# STM32H745xx register map
File version: 1.0
Registers are 32-bit, access not given, reset 0x0 unless marked. A register's access mark holds for its fields unless they carry their own. Offsets are from the block's base; [hi:lo] are bit positions; {n}, {i} and the like mark numbered series; 'fields as' and 'values as' point back to an identical list.

## MDMA
Base 0x52000000
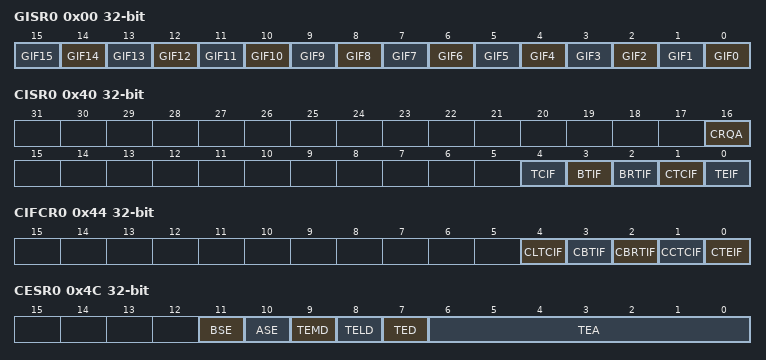
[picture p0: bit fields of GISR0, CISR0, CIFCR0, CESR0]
0x00 GISR0
  [n] GIF{n} (n=0..15)
0x40 CISR0
  [16] CRQA, [4] TCIF, [3] BTIF, [2] BRTIF, [1] CTCIF, [0] TEIF
0x44 CIFCR0
  [4] CLTCIF, [3] CBTIF, [2] CBRTIF, [1] CCTCIF, [0] CTEIF
0x4C CESR0
  [11] BSE, [10] ASE, [9] TEMD, [8] TELD, [7] TED, [6:0] TEA
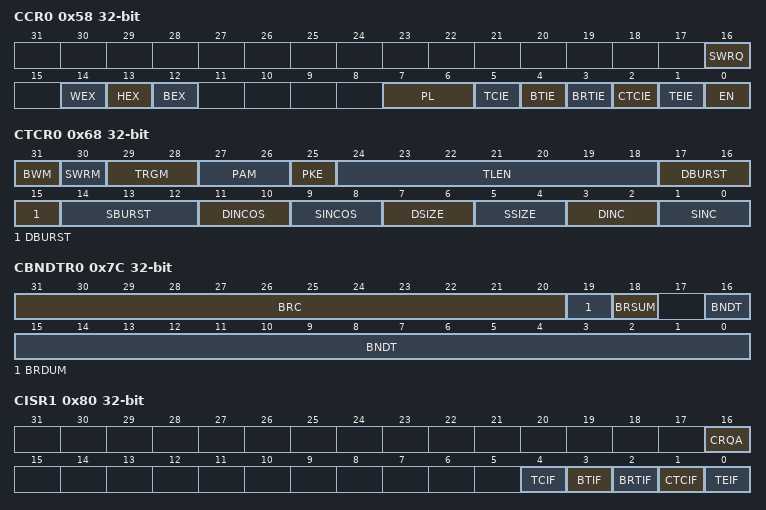
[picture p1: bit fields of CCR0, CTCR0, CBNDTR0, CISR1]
0x58 CCR0
  [16] SWRQ, [14] WEX, [13] HEX, [12] BEX, [7:6] PL, [5] TCIE, [4] BTIE, [3] BRTIE, [2] CTCIE, [1] TEIE, [0] EN
0x68 CTCR0
  [31] BWM, [30] SWRM, [29:28] TRGM, [27:26] PAM, [25] PKE, [24:18] TLEN, [17:15] DBURST, [14:12] SBURST, [11:10] DINCOS, [9:8] SINCOS, [7:6] DSIZE, [5:4] SSIZE, [3:2] DINC, [1:0] SINC
0x7C CBNDTR0
  [31:20] BRC, [19] BRDUM, [18] BRSUM, [16:0] BNDT
0x80 CISR1
  [16] CRQA, [4] TCIF, [3] BTIF, [2] BRTIF, [1] CTCIF, [0] TEIF
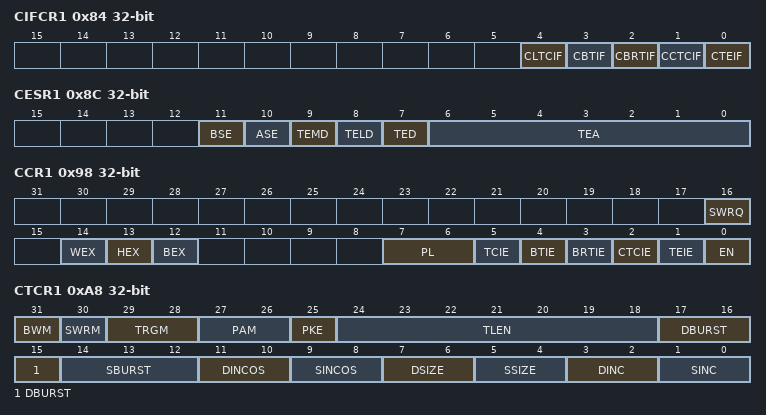
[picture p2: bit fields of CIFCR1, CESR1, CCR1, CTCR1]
0x84 CIFCR1
  [4] CLTCIF, [3] CBTIF, [2] CBRTIF, [1] CCTCIF, [0] CTEIF
0x8C CESR1
  [11] BSE, [10] ASE, [9] TEMD, [8] TELD, [7] TED, [6:0] TEA
0x94 CSAR0
  [31:0] SAR
0x98 CCR1
  fields as CCR0
0xA8 CTCR1
  fields as CTCR0
0xB0 CDAR0
  [31:0] DAR
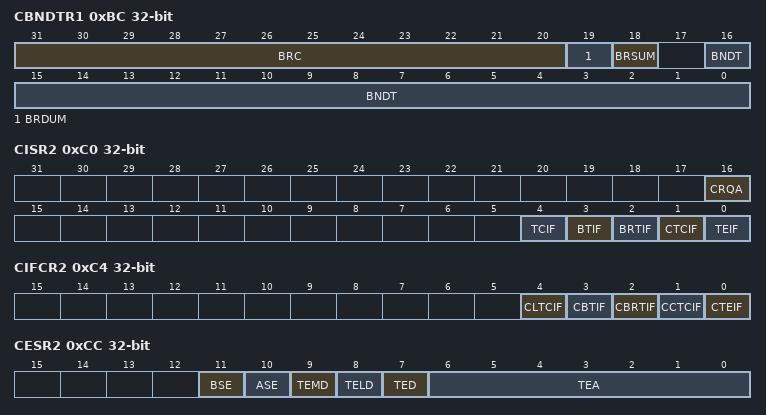
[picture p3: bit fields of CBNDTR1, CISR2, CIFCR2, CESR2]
0xBC CBNDTR1
  [31:20] BRC, [19] BRDUM, [18] BRSUM, [16:0] BNDT
0xC0 CISR2
  [16] CRQA, [4] TCIF, [3] BTIF, [2] BRTIF, [1] CTCIF, [0] TEIF
0xC4 CIFCR2
  [4] CLTCIF, [3] CBTIF, [2] CBRTIF, [1] CCTCIF, [0] CTEIF
0xCC CESR2
  [11] BSE, [10] ASE, [9] TEMD, [8] TELD, [7] TED, [6:0] TEA
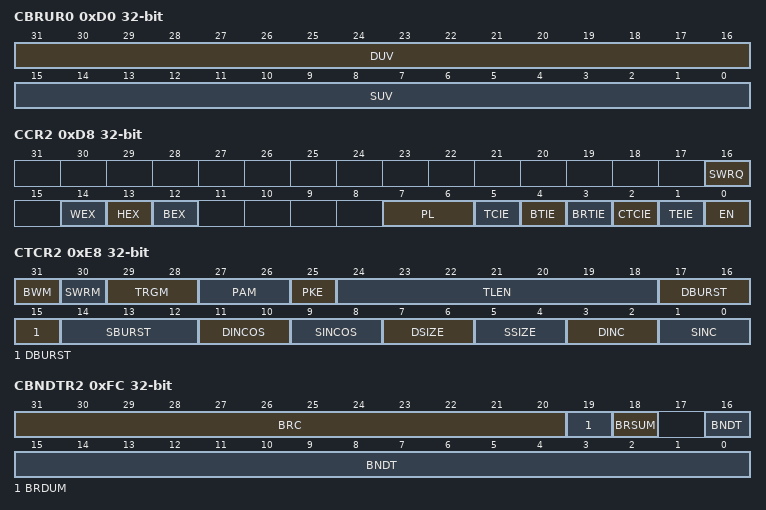
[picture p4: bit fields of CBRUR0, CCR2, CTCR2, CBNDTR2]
0xD0 CBRUR0
  [31:16] DUV, [15:0] SUV
0xD4 CSAR1
  [31:0] SAR
0xD8 CCR2
  fields as CCR0
0xE8 CTCR2
  fields as CTCR0
0xF0 CDAR1
  [31:0] DAR
0xF4 CLAR0
  [31:0] LAR
0xFC CBNDTR2
  [31:20] BRC, [19] BRDUM, [18] BRSUM, [16:0] BNDT
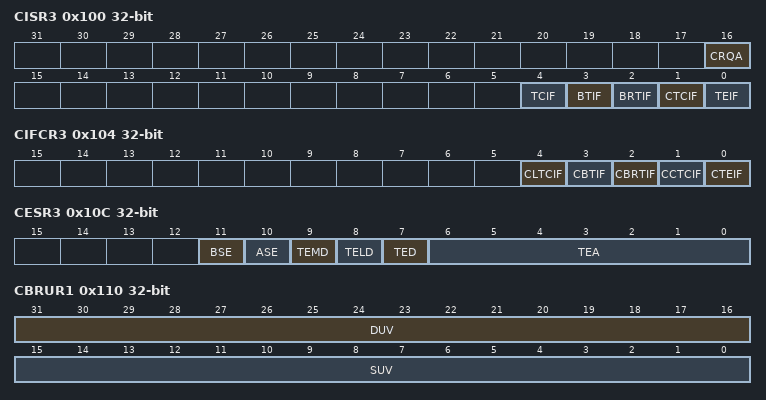
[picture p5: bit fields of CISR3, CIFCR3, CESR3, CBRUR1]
0x100 CISR3
  [16] CRQA, [4] TCIF, [3] BTIF, [2] BRTIF, [1] CTCIF, [0] TEIF
0x104 CIFCR3
  [4] CLTCIF, [3] CBTIF, [2] CBRTIF, [1] CCTCIF, [0] CTEIF
0x10C CESR3
  [11] BSE, [10] ASE, [9] TEMD, [8] TELD, [7] TED, [6:0] TEA
0x110 CBRUR1
  [31:16] DUV, [15:0] SUV
0x114 CSAR2
  [31:0] SAR
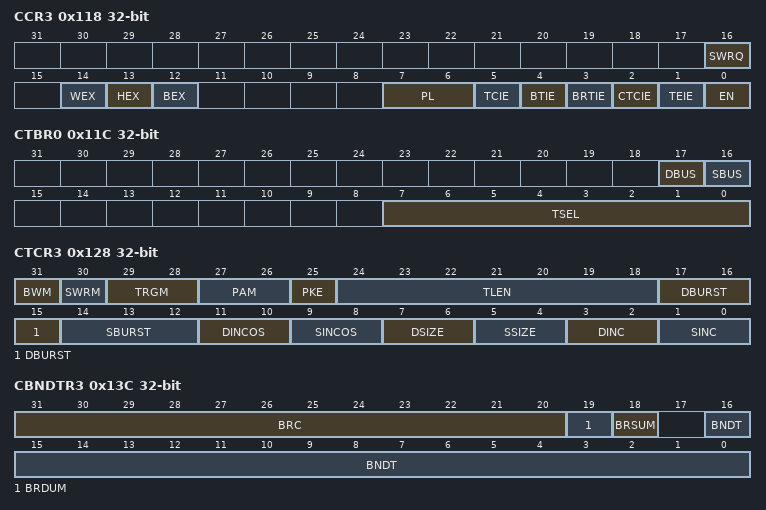
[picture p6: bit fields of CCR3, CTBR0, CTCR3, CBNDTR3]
0x118 CCR3
  fields as CCR0
0x11C CTBR0
  [17] DBUS, [16] SBUS, [7:0] TSEL
0x128 CTCR3
  fields as CTCR0
0x130 CDAR2
  [31:0] DAR
0x134 CLAR1
  [31:0] LAR
0x13C CBNDTR3
  [31:20] BRC, [19] BRDUM, [18] BRSUM, [16:0] BNDT
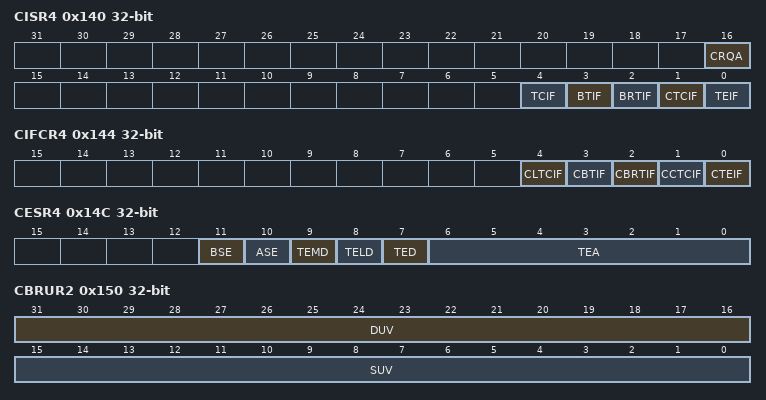
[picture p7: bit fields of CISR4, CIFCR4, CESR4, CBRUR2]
0x140 CISR4
  [16] CRQA, [4] TCIF, [3] BTIF, [2] BRTIF, [1] CTCIF, [0] TEIF
0x144 CIFCR4
  [4] CLTCIF, [3] CBTIF, [2] CBRTIF, [1] CCTCIF, [0] CTEIF
0x14C CMAR0
  [31:0] MAR
0x14C CESR4
  [11] BSE, [10] ASE, [9] TEMD, [8] TELD, [7] TED, [6:0] TEA
0x150 CBRUR2
  [31:16] DUV, [15:0] SUV
0x154 CSAR3
  [31:0] SAR
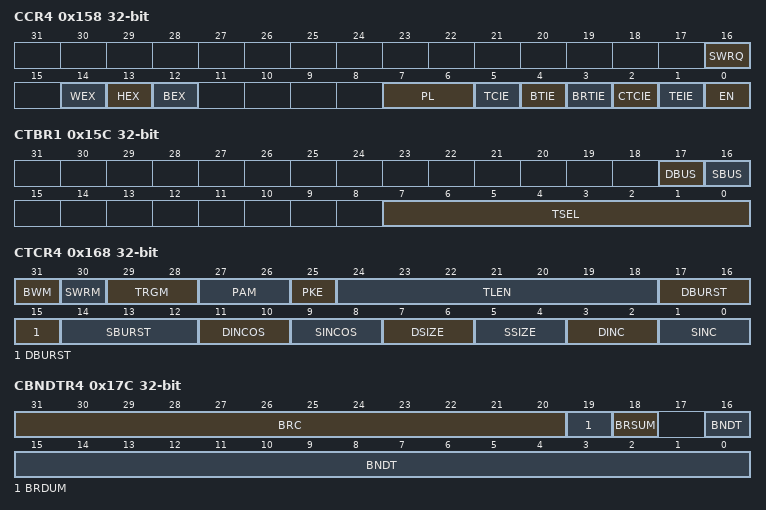
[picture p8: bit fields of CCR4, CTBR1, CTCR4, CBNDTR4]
0x158 CCR4
  fields as CCR0
0x15C CTBR1
  [17] DBUS, [16] SBUS, [7:0] TSEL
0x168 CTCR4
  fields as CTCR0
0x170 CDAR3
  [31:0] DAR
0x174 CLAR2
  [31:0] LAR
0x17C CBNDTR4
  [31:20] BRC, [19] BRDUM, [18] BRSUM, [16:0] BNDT
0x180 CMDR0
  [31:0] MDR
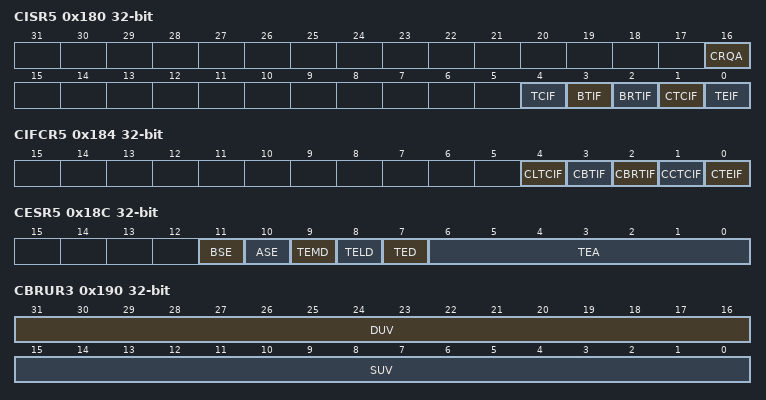
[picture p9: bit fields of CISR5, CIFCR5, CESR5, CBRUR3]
0x180 CISR5
  [16] CRQA, [4] TCIF, [3] BTIF, [2] BRTIF, [1] CTCIF, [0] TEIF
0x184 CIFCR5
  [4] CLTCIF, [3] CBTIF, [2] CBRTIF, [1] CCTCIF, [0] CTEIF
0x18C CMAR1
  [31:0] MAR
0x18C CESR5
  [11] BSE, [10] ASE, [9] TEMD, [8] TELD, [7] TED, [6:0] TEA
0x190 CBRUR3
  [31:16] DUV, [15:0] SUV
0x194 CSAR4
  [31:0] SAR
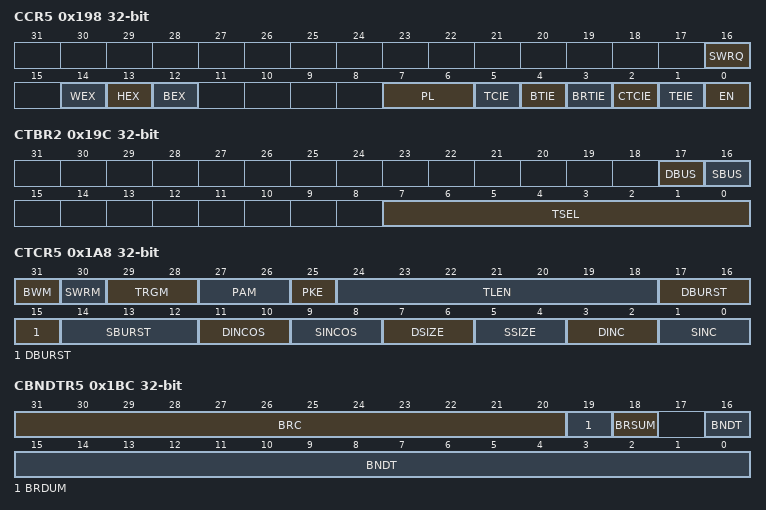
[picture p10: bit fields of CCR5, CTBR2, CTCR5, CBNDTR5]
0x198 CCR5
  fields as CCR0
0x19C CTBR2
  [17] DBUS, [16] SBUS, [7:0] TSEL
0x1A8 CTCR5
  fields as CTCR0
0x1B0 CDAR4
  [31:0] DAR
0x1B4 CLAR3
  [31:0] LAR
0x1BC CBNDTR5
  [31:20] BRC, [19] BRDUM, [18] BRSUM, [16:0] BNDT
0x1C0 CMDR1
  [31:0] MDR
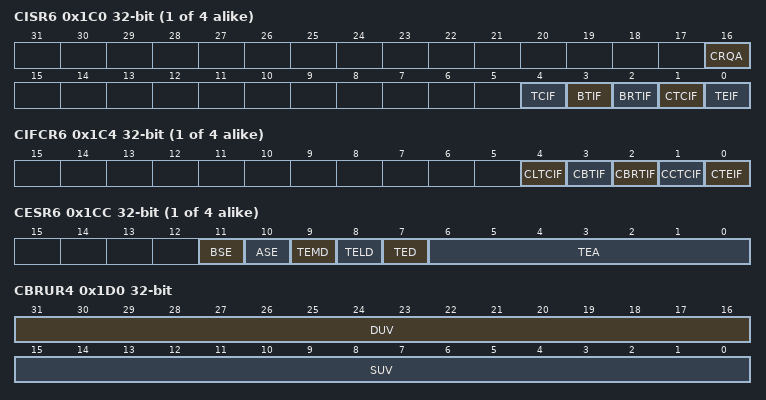
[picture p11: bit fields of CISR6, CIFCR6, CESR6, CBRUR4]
{0x40+0x40*i} CISR{i} (i=6..9)
  [16] CRQA, [4] TCIF, [3] BTIF, [2] BRTIF, [1] CTCIF, [0] TEIF
{0x44+0x40*i} CIFCR{i} (i=6..9)
  [4] CLTCIF, [3] CBTIF, [2] CBRTIF, [1] CCTCIF, [0] CTEIF
0x1CC CMAR2
  [31:0] MAR
{0x4C+0x40*i} CESR{i} (i=6..9)
  [11] BSE, [10] ASE, [9] TEMD, [8] TELD, [7] TED, [6:0] TEA
0x1D0 CBRUR4
  [31:16] DUV, [15:0] SUV
0x1D4 CSAR5
  [31:0] SAR
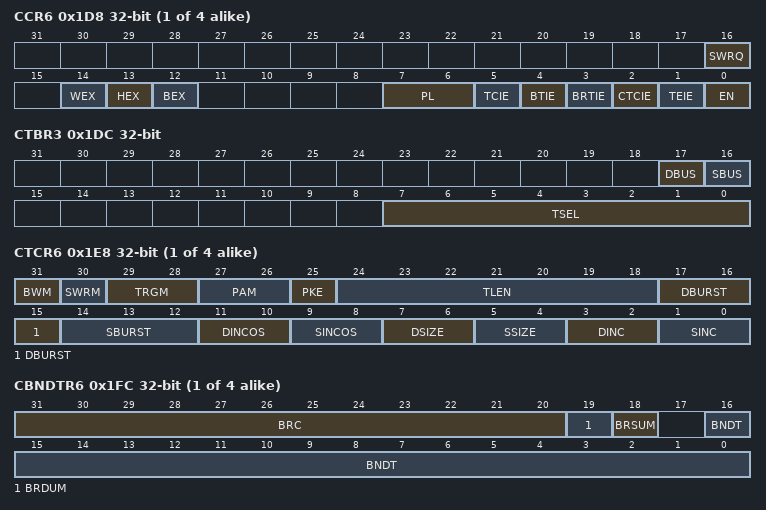
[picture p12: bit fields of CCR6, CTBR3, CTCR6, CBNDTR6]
{0x58+0x40*i} CCR{i} (i=6..9)
  fields as CCR0
0x1DC CTBR3
  [17] DBUS, [16] SBUS, [7:0] TSEL
{0x68+0x40*i} CTCR{i} (i=6..9)
  fields as CTCR0
0x1F0 CDAR5
  [31:0] DAR
0x1F4 CLAR4
  [31:0] LAR
{0x7C+0x40*i} CBNDTR{i} (i=6..9)
  [31:20] BRC, [19] BRDUM, [18] BRSUM, [16:0] BNDT
0x200 CMDR2
  [31:0] MDR
0x20C CMAR3
  [31:0] MAR
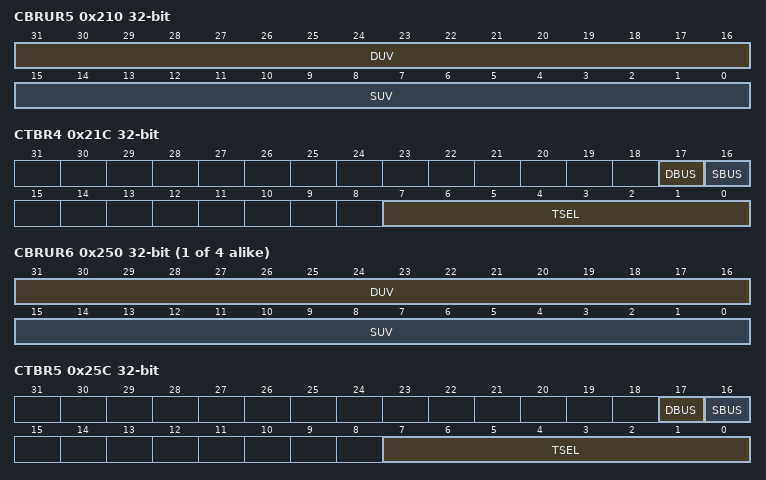
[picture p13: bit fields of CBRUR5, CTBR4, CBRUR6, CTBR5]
0x210 CBRUR5
  [31:16] DUV, [15:0] SUV
{0x94+0x40*i} CSAR{i} (i=6..9)
  [31:0] SAR
0x21C CTBR4
  [17] DBUS, [16] SBUS, [7:0] TSEL
{0xB0+0x40*i} CDAR{i} (i=6..9)
  [31:0] DAR
0x234 CLAR5
  [31:0] LAR
0x240 CMDR3
  [31:0] MDR
0x24C CMAR4
  [31:0] MAR
{0xD0+0x40*i} CBRUR{i} (i=6..9)
  [31:16] DUV, [15:0] SUV
0x25C CTBR5
  [17] DBUS, [16] SBUS, [7:0] TSEL
{0xF4+0x40*i} CLAR{i} (i=6..9)
  [31:0] LAR
0x280 CMDR4
  [31:0] MDR
0x28C CMAR5
  [31:0] MAR
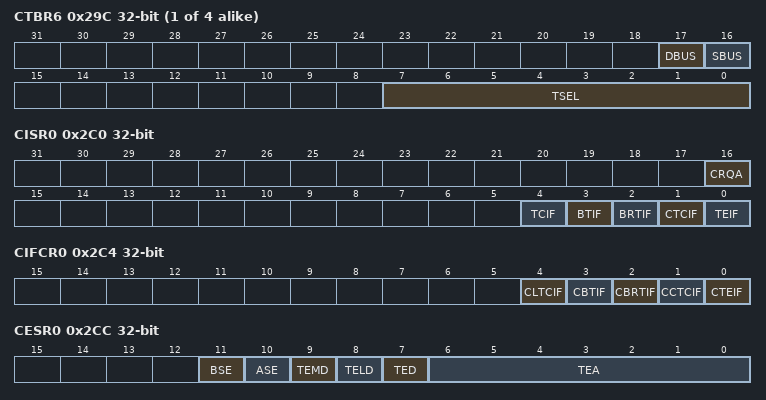
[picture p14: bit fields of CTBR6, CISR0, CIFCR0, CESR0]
{0x11C+0x40*i} CTBR{i} (i=6..9)
  [17] DBUS, [16] SBUS, [7:0] TSEL
0x2C0 CMDR5
  [31:0] MDR
0x2C0 CISR0
  [16] CRQA, [4] TCIF, [3] BTIF, [2] BRTIF, [1] CTCIF, [0] TEIF
0x2C4 CIFCR0
  [4] CLTCIF, [3] CBTIF, [2] CBRTIF, [1] CCTCIF, [0] CTEIF
{0x14C+0x40*i} CMAR{i} (i=6..9)
  [31:0] MAR
0x2CC CESR0
  [11] BSE, [10] ASE, [9] TEMD, [8] TELD, [7] TED, [6:0] TEA
0x2D8 CCR0
  fields as CCR0
0x2E8 CTCR0
  fields as CTCR0
0x2FC CBNDTR0
  [31:20] BRC, [19] BRDUM, [18] BRSUM, [16:0] BNDT
{0x180+0x40*i} CMDR{i} (i=6..9)
  [31:0] MDR
0x300 CISR1
  [16] CRQA, [4] TCIF, [3] BTIF, [2] BRTIF, [1] CTCIF, [0] TEIF
0x304 CIFCR1
  [4] CLTCIF, [3] CBTIF, [2] CBRTIF, [1] CCTCIF, [0] CTEIF
0x30C CESR1
  [11] BSE, [10] ASE, [9] TEMD, [8] TELD, [7] TED, [6:0] TEA
0x314 CSAR0
  [31:0] SAR
0x318 CCR1
  fields as CCR0
0x328 CTCR1
  fields as CTCR0
0x330 CDAR0
  [31:0] DAR
0x33C CBNDTR1
  [31:20] BRC, [19] BRDUM, [18] BRSUM, [16:0] BNDT
0x340 CISR2
  [16] CRQA, [4] TCIF, [3] BTIF, [2] BRTIF, [1] CTCIF, [0] TEIF
0x344 CIFCR2
  [4] CLTCIF, [3] CBTIF, [2] CBRTIF, [1] CCTCIF, [0] CTEIF
0x34C CESR2
  [11] BSE, [10] ASE, [9] TEMD, [8] TELD, [7] TED, [6:0] TEA
0x350 CBRUR0
  [31:16] DUV, [15:0] SUV
0x354 CSAR1
  [31:0] SAR
0x358 CCR2
  fields as CCR0
0x368 CTCR2
  fields as CTCR0
0x370 CDAR1
  [31:0] DAR
0x374 CLAR0
  [31:0] LAR
0x37C CBNDTR2
  [31:20] BRC, [19] BRDUM, [18] BRSUM, [16:0] BNDT
0x380 CISR3
  [16] CRQA, [4] TCIF, [3] BTIF, [2] BRTIF, [1] CTCIF, [0] TEIF
0x384 CIFCR3
  [4] CLTCIF, [3] CBTIF, [2] CBRTIF, [1] CCTCIF, [0] CTEIF
0x38C CESR3
  [11] BSE, [10] ASE, [9] TEMD, [8] TELD, [7] TED, [6:0] TEA
0x390 CBRUR1
  [31:16] DUV, [15:0] SUV
0x394 CSAR2
  [31:0] SAR
0x398 CCR3
  fields as CCR0
0x39C CTBR0
  [17] DBUS, [16] SBUS, [7:0] TSEL
0x3A8 CTCR3
  fields as CTCR0
0x3B0 CDAR2
  [31:0] DAR
0x3B4 CLAR1
  [31:0] LAR
0x3BC CBNDTR3
  [31:20] BRC, [19] BRDUM, [18] BRSUM, [16:0] BNDT
0x3C0 CISR4
  [16] CRQA, [4] TCIF, [3] BTIF, [2] BRTIF, [1] CTCIF, [0] TEIF
0x3C4 CIFCR4
  [4] CLTCIF, [3] CBTIF, [2] CBRTIF, [1] CCTCIF, [0] CTEIF
0x3CC CMAR0
  [31:0] MAR
0x3CC CESR4
  [11] BSE, [10] ASE, [9] TEMD, [8] TELD, [7] TED, [6:0] TEA
0x3D0 CBRUR2
  [31:16] DUV, [15:0] SUV
0x3D4 CSAR3
  [31:0] SAR
0x3D8 CCR4
  fields as CCR0
0x3DC CTBR1
  [17] DBUS, [16] SBUS, [7:0] TSEL
0x3E8 CTCR4
  fields as CTCR0
0x3F0 CDAR3
  [31:0] DAR
0x3F4 CLAR2
  [31:0] LAR
0x3FC CBNDTR4
  [31:20] BRC, [19] BRDUM, [18] BRSUM, [16:0] BNDT
0x400 CMDR0
  [31:0] MDR
0x400 CISR5
  [16] CRQA, [4] TCIF, [3] BTIF, [2] BRTIF, [1] CTCIF, [0] TEIF
0x404 CIFCR5
  [4] CLTCIF, [3] CBTIF, [2] CBRTIF, [1] CCTCIF, [0] CTEIF
0x40C CMAR1
  [31:0] MAR
0x40C CESR5
  [11] BSE, [10] ASE, [9] TEMD, [8] TELD, [7] TED, [6:0] TEA
0x410 CBRUR3
  [31:16] DUV, [15:0] SUV
0x414 CSAR4
  [31:0] SAR
0x418 CCR5
  fields as CCR0
0x41C CTBR2
  [17] DBUS, [16] SBUS, [7:0] TSEL
0x428 CTCR5
  fields as CTCR0
0x430 CDAR4
  [31:0] DAR
0x434 CLAR3
  [31:0] LAR
0x43C CBNDTR5
  [31:20] BRC, [19] BRDUM, [18] BRSUM, [16:0] BNDT
0x440 CMDR1
  [31:0] MDR
0x44C CMAR2
  [31:0] MAR
0x450 CBRUR4
  [31:16] DUV, [15:0] SUV
0x454 CSAR5
  [31:0] SAR
0x45C CTBR3
  [17] DBUS, [16] SBUS, [7:0] TSEL
0x470 CDAR5
  [31:0] DAR
0x474 CLAR4
  [31:0] LAR
0x480 CMDR2
  [31:0] MDR
0x48C CMAR3
  [31:0] MAR
0x490 CBRUR5
  [31:16] DUV, [15:0] SUV
0x49C CTBR4
  [17] DBUS, [16] SBUS, [7:0] TSEL
0x4B4 CLAR5
  [31:0] LAR
0x4C0 CMDR3
  [31:0] MDR
0x4CC CMAR4
  [31:0] MAR
0x4DC CTBR5
  [17] DBUS, [16] SBUS, [7:0] TSEL
0x500 CMDR4
  [31:0] MDR
0x50C CMAR5
  [31:0] MAR
0x540 CMDR5
  [31:0] MDR
